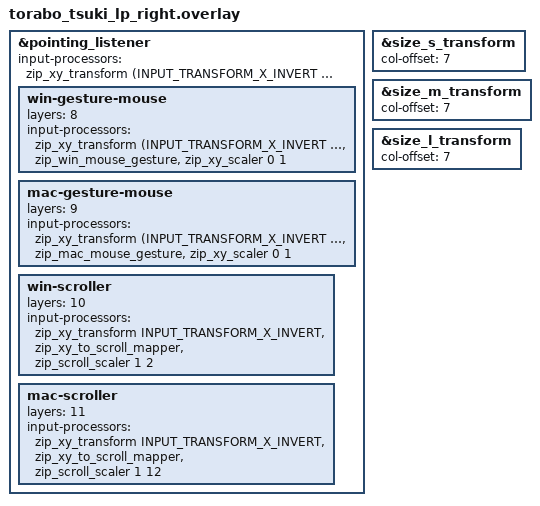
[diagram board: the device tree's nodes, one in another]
#define TORABO_TSUKI_LP_RIGHT 1
#define TORABO_TSUKI_LP_MATRIX_COL_OFFSET 7

#include "torabo_tsuki_lp.dtsi"
#include <input/processors.dtsi>
#include <dt-bindings/zmk/input_transform.h>

&pointing_listener {
    // Keep typing on the base layer while moving the ball; use click combos.
    input-processors =
        <&zip_xy_transform (INPUT_TRANSFORM_X_INVERT | INPUT_TRANSFORM_Y_INVERT)>;

    win-gesture-mouse {
        layers = <8>;
        input-processors =
            <&zip_xy_transform (INPUT_TRANSFORM_X_INVERT | INPUT_TRANSFORM_Y_INVERT)>,
            <&zip_win_mouse_gesture>,
            <&zip_xy_scaler 0 1>;
    };

    mac-gesture-mouse {
        layers = <9>;
        input-processors =
            <&zip_xy_transform (INPUT_TRANSFORM_X_INVERT | INPUT_TRANSFORM_Y_INVERT)>,
            <&zip_mac_mouse_gesture>,
            <&zip_xy_scaler 0 1>;
    };

    win-scroller {
        layers = <10>;
        input-processors =
            <&zip_xy_transform INPUT_TRANSFORM_X_INVERT>,
            <&zip_xy_to_scroll_mapper>,
            <&zip_scroll_scaler 1 2>;
    };

    mac-scroller {
        layers = <11>;
        input-processors =
            <&zip_xy_transform INPUT_TRANSFORM_X_INVERT>,
            <&zip_xy_to_scroll_mapper>,
            <&zip_scroll_scaler 1 12>;
    };
};

&size_s_transform {
    col-offset = <7>;
};

&size_m_transform {
    col-offset = <7>;
};

&size_l_transform {
    col-offset = <7>;
};
